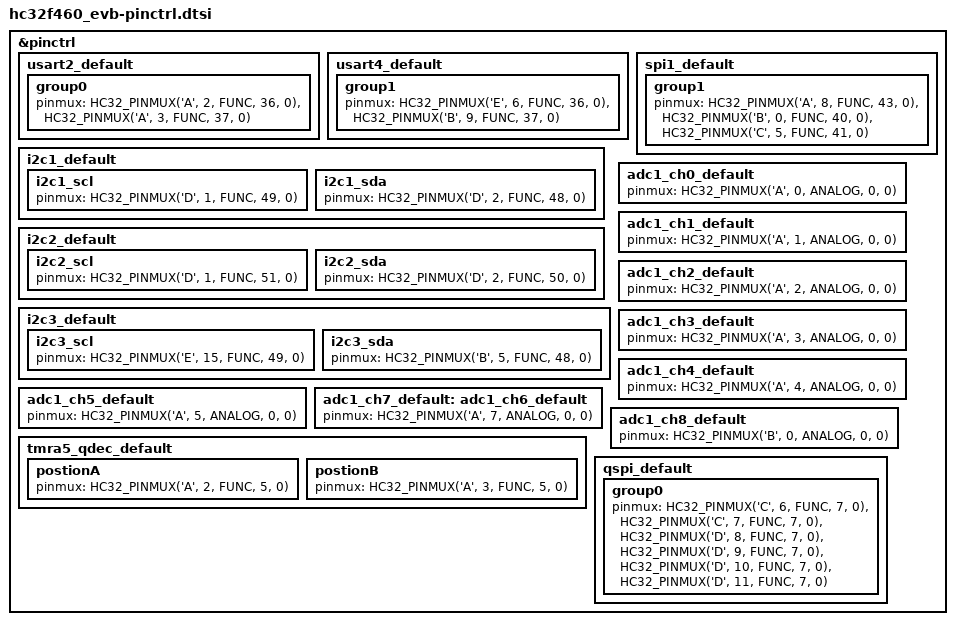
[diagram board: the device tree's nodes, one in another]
/*
 * Copyright (C) 2022-2024, Xiaohua Semiconductor Co., Ltd.
 * SPDX-License-Identifier: Apache-2.0
 */

#include <dt-bindings/pinctrl/hc32-pinctrl.h>

&pinctrl {
	usart2_default: usart2_default {
		group0 {
			pinmux = <HC32_PINMUX('A', 2, FUNC, 36, 0)>,
				<HC32_PINMUX('A', 3, FUNC, 37, 0)>;
		};
	};

	usart4_default: usart4_default {
		group1 {
			pinmux = <HC32_PINMUX('E', 6, FUNC, 36, 0)>,
				<HC32_PINMUX('B', 9, FUNC, 37, 0)>;
		};
	};

	spi1_default: spi1_default {
		group1 {
			pinmux = <HC32_PINMUX('A', 8, FUNC, 43, 0)>, /*  SCK */
				 <HC32_PINMUX('B', 0, FUNC, 40, 0)>, /* MOSI */
				 <HC32_PINMUX('C', 5, FUNC, 41, 0)>; /* MISO */
		};
	};

	i2c1_default: i2c1_default {
		i2c1_scl {
			pinmux = <HC32_PINMUX('D', 1, FUNC, 49, 0)>;
		};
		i2c1_sda {
			pinmux = <HC32_PINMUX('D', 2, FUNC, 48, 0)>;
		};
	};

	i2c2_default: i2c2_default {
		i2c2_scl {
			pinmux = <HC32_PINMUX('D', 1, FUNC, 51, 0)>;
		};
		i2c2_sda {
			pinmux = <HC32_PINMUX('D', 2, FUNC, 50, 0)>;
		};
	};

	i2c3_default: i2c3_default {
		i2c3_scl {
			pinmux = <HC32_PINMUX('E', 15, FUNC, 49, 0)>;
		};
		i2c3_sda {
			pinmux = <HC32_PINMUX('B', 5, FUNC, 48, 0)>;
		};
	};

	adc1_ch0_default: adc1_ch0_default {
			pinmux = <HC32_PINMUX('A', 0, ANALOG, 0, 0)>; /* ADC12_IN0 */
	};
	adc1_ch1_default: adc1_ch1_default {
		pinmux = <HC32_PINMUX('A', 1, ANALOG, 0, 0)>; /* ADC12_IN1 */
	};
	adc1_ch2_default: adc1_ch2_default {
		pinmux = <HC32_PINMUX('A', 2, ANALOG, 0, 0)>; /* ADC12_IN2 */
	};
	adc1_ch3_default: adc1_ch3_default {
		pinmux = <HC32_PINMUX('A', 3, ANALOG, 0, 0)>; /* ADC12_IN3 */
	};
	adc1_ch4_default: adc1_ch4_default {
		pinmux = <HC32_PINMUX('A', 4, ANALOG, 0, 0)>; /* ADC12_IN4 */
	};
	adc1_ch5_default: adc1_ch5_default {
		pinmux = <HC32_PINMUX('A', 5, ANALOG, 0, 0)>; /* ADC12_IN5 */
	};
	adc1_ch7_default: adc1_ch6_default {
		pinmux = <HC32_PINMUX('A', 7, ANALOG, 0, 0)>; /* ADC12_IN7 */
	};
	adc1_ch8_default: adc1_ch8_default {
		pinmux = <HC32_PINMUX('B', 0, ANALOG, 0, 0)>; /* ADC12_IN8 */
	};
	tmra5_qdec_default: tmra5_qdec_default {
		postionA {
			pinmux = <HC32_PINMUX('A', 2, FUNC, 5, 0)>;
		};
		postionB {
			pinmux = <HC32_PINMUX('A', 3, FUNC, 5, 0)>;
		};
	};

	qspi_default: qspi_default {
		group0 {
			pinmux = <HC32_PINMUX('C', 6, FUNC, 7, 0)>, /* qspi_clk */
			<HC32_PINMUX('C', 7, FUNC, 7, 0)>, /* qspi_cs */
			<HC32_PINMUX('D', 8, FUNC, 7, 0)>, /* qspi_io0 */
			<HC32_PINMUX('D', 9, FUNC, 7, 0)>, /* qspi_io1 */
			<HC32_PINMUX('D', 10, FUNC, 7, 0)>, /* qspi_io2 */
			<HC32_PINMUX('D', 11, FUNC, 7, 0)>; /* qspi_io3 */
		};
	};
};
